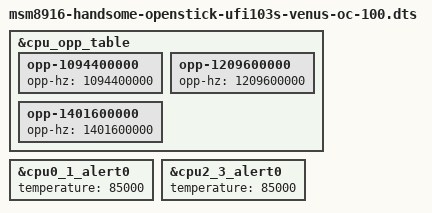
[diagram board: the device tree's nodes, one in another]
// SPDX-License-Identifier: GPL-2.0-only
/*
 * Handsome OpenStick UFI103s - Venus codec + ~100 MHz CPU frequency steps
 *
 * Deliberately coarse: one step per ~100 MHz instead of the 19.2 MHz grid the
 * A53 PLL could provide, because a fine table is not worth the extra steps here.
 *
 *   stock table:  200 / 400 / 800 / 998.4 MHz
 *   added here:   1094.4 / 1209.6 / 1401.6 MHz
 *   gaps above:   96 / 115.2 / 192 MHz
 *
 * Every rate here is a stock a53pll rate, so this variant needs NO kernel
 * change at all -- only the DTS.  (1300 MHz is skipped on purpose: the nearest
 * stock rate would be 1305.6 MHz, which is not in the upstream a53pll table and
 * would have required a built-in clock-driver patch.)
 *
 * The CPU passive-cooling trip is 85 C (critical stays 110 C): bursts hold the
 * top step longer, sustained load is still throttled automatically.  Note the
 * measured ceiling -- the core stops getting faster at about 1209.6 MHz -- so
 * the two steps above it buy headroom for short bursts, not sustained speed.
 */

#include "msm8916-handsome-openstick-ufi103s-venus.dts"

&cpu_opp_table {
	opp-1094400000 { opp-hz = /bits/ 64 <1094400000>; };
	opp-1209600000 { opp-hz = /bits/ 64 <1209600000>; };
	opp-1401600000 { opp-hz = /bits/ 64 <1401600000>; };
};

&cpu0_1_alert0 {
	temperature = <85000>;
};

&cpu2_3_alert0 {
	temperature = <85000>;
};
